# LPC13xx register map
File version: 0.3
CPU: CM3 r0p0, little endian, no MPU, no FPU, 3 interrupt priority bits
Registers are 32-bit, read-write, reset 0x0 unless marked. A register's access mark holds for its fields unless they carry their own. Offsets are from the block's base; [hi:lo] are bit positions; {n}, {i} and the like mark numbered series.

## USB — USB device
Base 0x40020000
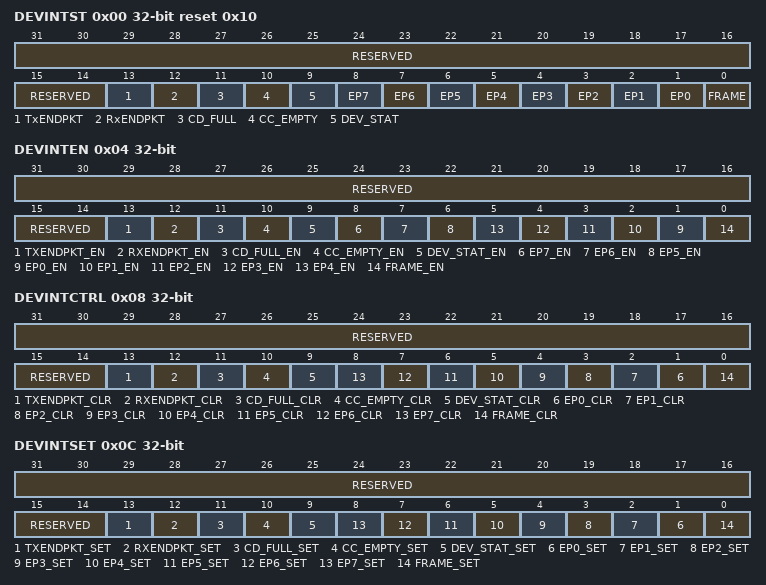
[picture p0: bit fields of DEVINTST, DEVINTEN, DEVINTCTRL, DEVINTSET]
0x00 DEVINTST ro reset 0x10 — USB Device Interrupt Status
  [31:14] RESERVED — Reserved, user software should not write ones to reserved bits. The value read from a reserved bit is not defined.
  [13] TxENDPKT — The number of data bytes transferred to the endpoint buffer equals the number of bytes programmed in the TxPacket length register (USBTxPLen). 0 = no interrupt. 1 = interrupt pending.
  [12] RxENDPKT — The current packet in the endpoint buffer is transferred to the CPU. 0 = no interrupt. 1 = interrupt pending.
  [11] CD_FULL — Command data register (USBCmdData) is full (Data can be read now). 0 = no interrupt. 1 = interrupt pending.
  [10] CC_EMPTY — The command code register (USBCmdCode) is empty (New command can be written). 0 = no interrupt. 1 = interrupt pending.
  [9] DEV_STAT — Set when USB Bus reset, USB suspend change, or Connect change event occurs. Refer to Section 10.11.7. 0 = no interrupt. 1 = interrupt pending.
  [n+1] EP{n} (n=0..7) — USB core interrupt for physical endpoint {n}. 0 = no interrupt. 1 = interrupt pending.
  [0] FRAME — The frame interrupt occurs every 1 ms. This is used in isochronous packet transfers. 0 = no interrupt. 1 = interrupt pending.
0x04 DEVINTEN — USB Device Interrupt Enable
  [31:14] RESERVED — Reserved, user software should not write ones to reserved bits. The value read from a reserved bit is not defined.
  [13] TXENDPKT_EN — The number of data bytes transferred to the endpoint buffer equals the number of bytes programmed in the TxPacket length register (USBTxPLen). 0 = no interrupt generated. 1 = interrupt generated when the corresponding bit in USBDevIntSt is set.
  [12] RXENDPKT_EN — The current packet in the endpoint buffer is transferred to the CPU. 0 = no interrupt generated. 1 = interrupt generated when the corresponding bit in USBDevIntSt is set.
  [11] CD_FULL_EN — Command data register (USBCmdData) is full (Data can be read now). 0 = no interrupt generated. 1 = interrupt generated when the corresponding bit in USBDevIntSt is set.
  [10] CC_EMPTY_EN — The command code register (USBCmdCode) is empty (New command can be written). 0 = no interrupt generated. 1 = interrupt generated when the corresponding bit in USBDevIntSt is set.
  [9] DEV_STAT_EN — Set when USB Bus reset, USB suspend change, or Connect change event occurs. 0 = no interrupt generated. 1 = interrupt generated when the corresponding bit in USBDevIntSt is set.
  [8] EP7_EN — USB core interrupt for physical endpoint 7. 0 = no interrupt generated. 1 = interrupt generated when the corresponding bit in USBDevIntSt is set.
  [7] EP6_EN — USB core interrupt for physical endpoint 6. 0 = no interrupt generated. 1 = interrupt generated when the corresponding bit in USBDevIntSt is set.
  [6] EP5_EN — USB core interrupt for physical endpoint 5. 0 = no interrupt. 1 = interrupt pending.
  [n+1] EP{n}_EN (n=0..4) — USB core interrupt for physical endpoint {n}. 0 = no interrupt generated. 1 = interrupt generated when the corresponding bit in USBDevIntSt is set.
  [0] FRAME_EN — Frame interrupt . For isochronous packet transfers. 0 = no interrupt generated. 1 = interrupt generated when the corresponding bit in USBDevIntSt is set.
0x08 DEVINTCTRL wo — USB Device Interrupt Clear
  [31:14] RESERVED — Reserved, user software should not write ones to reserved bits. The value read from a reserved bit is not defined.
  [13] TXENDPKT_CLR — The number of data bytes transferred to the endpoint buffer equals the number of bytes programmed in the TxPacket length register (USBTxPLen). 0 = no effect. 1 = the corresponding bit in USBDevIntSt is cleared.
  [12] RXENDPKT_CLR — The current packet in the endpoint buffer is transferred to the CPU. 0 = no effect. 1 = the corresponding bit in USBDevIntSt is cleared.
  [11] CD_FULL_CLR — Command data register (USBCmdData) is full (Data can be read now). 0 = no effect. 1 = the corresponding bit in USBDevIntSt is cleared.
  [10] CC_EMPTY_CLR — The command code register (USBCmdCode) is empty (New command can be written). 0 = no effect. 1 = the corresponding bit in USBDevIntSt is cleared.
  [9] DEV_STAT_CLR — Set when USB Bus reset, USB suspend change, or Connect change event occurs. 0 = no effect. 1 = the corresponding bit in USBDevIntSt is cleared.
  [n+1] EP{n}_CLR (n=0..7) — USB core interrupt for physical endpoint {n}. 0 = no effect. 1 = the corresponding bit in USBDevIntSt is cleared.
  [0] FRAME_CLR — Frame interrupt . For isochronous packet transfers. 0 = no effect. 1 = the corresponding bit in USBDevIntSt is cleared.
0x0C DEVINTSET wo — USB Device Interrupt Set
  [31:14] RESERVED — Reserved, user software should not write ones to reserved bits. The value read from a reserved bit is not defined.
  [13] TXENDPKT_SET — The number of data bytes transferred to the endpoint buffer equals the number of bytes programmed in the TxPacket length register (USBTxPLen). 0 = no effect. 1 = the corresponding bit in USBDevIntSt is set.
  [12] RXENDPKT_SET — The current packet in the endpoint buffer is transferred to the CPU. 0 = no effect. 1 = the corresponding bit in USBDevIntSt is set.
  [11] CD_FULL_SET — Command data register (USBCmdData) is full (Data can be read now). 0 = no effect. 1 = the corresponding bit in USBDevIntSt is set.
  [10] CC_EMPTY_SET — The command code register (USBCmdCode) is empty (New command can be written). 0 = no effect. 1 = the corresponding bit in USBDevIntSt is set.
  [9] DEV_STAT_SET — Set when USB Bus reset, USB suspend change, or Connect change event occurs. 0 = no effect. 1 = the corresponding bit in USBDevIntSt is set.
  [n+1] EP{n}_SET (n=0..7) — USB core interrupt for physical endpoint {n}. 0 = no effect. 1 = the corresponding bit in USBDevIntSt is set.
  [0] FRAME_SET — Frame interrupt . For isochronous packet transfers. 0 = no effect. 1 = the corresponding bit in USBDevIntSt is set.
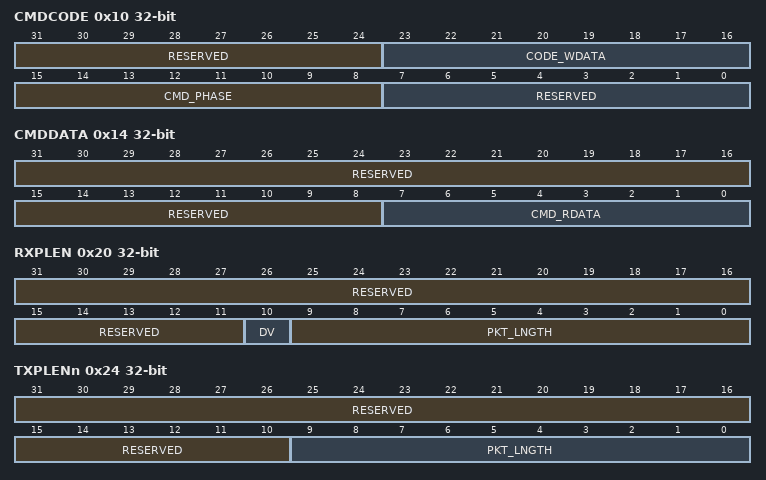
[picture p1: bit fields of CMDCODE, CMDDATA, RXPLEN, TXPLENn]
0x10 CMDCODE wo — USB Command Code
  [31:24] RESERVED — Reserved, user software should not write ones to reserved bits. The value read from a reserved bit is not defined.
  [23:16] CODE_WDATA — This is a multi-purpose field. When CMD_PHASE is Command or Read, this field contains the code for the command (CMD_CODE). When CMD_PHASE is Write, this field contains the command write data (CMD_WDATA).
  [15:8] CMD_PHASE — Command phase action
    1=WRITE; 2=READ; 5=COMMAND
  [7:0] RESERVED — Reserved, user software should not write ones to reserved bits. The value read from a reserved bit is not defined.
0x14 CMDDATA ro — USB Command Data
  [31:8] RESERVED — Reserved, user software should not write ones to reserved bits. The value read from a reserved bit is not defined.
  [7:0] CMD_RDATA — Command Read Data.
0x18 RXDATA ro — USB Receive Data
  [31:0] RX_DATA — Data received.
0x1C TXDATA wo — USB Transmit Data
  [31:0] TX_DATA — Transmit Data.
0x20 RXPLEN ro — USB Receive Packet Length
  [31:11] RESERVED — Reserved, user software should not write ones to reserved bits. The value read from a reserved bit is not defined.
  [10] DV — Data valid. This bit is useful for isochronous endpoints. Non-isochronous endpoints do not raise an interrupt when an erroneous data packet is received. But invalid data packet can be produced with a bus reset. For isochronous endpoints, data transfer will happen even if an erroneous packet is received. In this case DV bit will not be set for the packet.
    0=DATA_IS_INVALID_; 1=DATA_IS_VALID_
  [9:0] PKT_LNGTH — The remaining number of bytes to be read from the currently selected endpoint's buffer. When this field decrements to 0, the RxENDPKT bit will be set in USBDevIntSt.
0x24 TXPLENn wo — USB Transmit Packet Length
  [31:10] RESERVED — Reserved, user software should not write ones to reserved bits. The value read from a reserved bit is not defined.
  [9:0] PKT_LNGTH — The remaining number of bytes to be written to the selected endpoint buffer. This field is decremented by 4 by hardware after each write to USBTxData. When this field decrements to 0, the TxENDPKT bit will be set in USBDevIntSt.
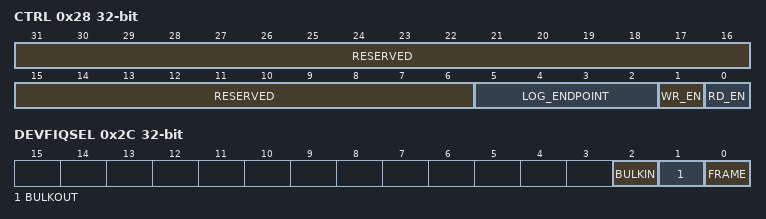
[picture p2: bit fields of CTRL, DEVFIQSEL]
0x28 CTRL — USB Control
  [31:6] RESERVED — Reserved, user software should not write ones to reserved bits. The value read from a reserved bit is not defined.
  [5:2] LOG_ENDPOINT — Logical Endpoint number.
  [1] WR_EN — Write mode control. Enables writing data to the IN endpoint buffer for the endpoint specified in the LOG_ENDPOINT field using the USBTxData register. This bit is cleared by hardware when the number of bytes in USBTxLen have been sent.
    0=WRITE_MODE_IS_DISABL (Write mode is disabled.); 1=WRITE_MODE_IS_ENABLE (Write mode is enabled.)
  [0] RD_EN — Read mode control. Enables reading data from the OUT endpoint buffer for the endpoint specified in the LOG_ENDPOINT field using the USBRxData register. This bit is cleared by hardware when the last word of the current packet is read from USBRxData.
    0=READ_MODE_IS_DISABLE (Read mode is disabled.); 1=READ_MODE_IS_ENABLED
0x2C DEVFIQSEL wo — USB Device FIQ select
  [2] BULKIN — Interrupt routing for bulk in endpoints For logical endpoint 3 (physical endpoints 6 and 7) only.
    0=LOWPRIORITY (BULKIN interrupt will be routed to the low-priority interrupt line IRQ.); 1=HIGHPRIORITY (BULKIN interrupt will be routed to the high-priority interrupt line FIQ.)
  [1] BULKOUT — Interrupt routing for bulk out endpoints For logical endpoint 3 (physical endpoints 6 and 7) only.
    0=LOWPRIORITY (BULKOUT interrupt will be routed to the low-priority interrupt line IRQ.); 1=HIGHPRIORITY (BULKOUT interrupt will be routed to the high-priority interrupt line FIQ.)
  [0] FRAME — This interrupt comes from a 1 KHz free running clock resynchronized on the incoming SoF tokens. This is to be used for isochronous packet transfer.
    0=LOWPRIORITY (FRAME interrupt will be routed to the low-priority interrupt line IRQ.); 1=HIGHPRIORITY (FRAME interrupt will be routed to the high-priority interrupt line FIQ.)
